VERSION ""

NS_ :

BS_:

BU_: Sensors BPR DIO PDU ELVIS ASSI ECU_LV Dashboard

BO_ 1824 Pushrods_back: 4 Sensors
 SG_ Pushrod_RB : 0|16@1+ (1,0) [0|65535] "" Vector__XXX
 SG_ Pushrod_LB : 16|16@1+ (1,0) [0|65535] "" Vector__XXX

BO_ 1825 Rockers: 4 Sensors
 SG_ Rocker_HAL_R : 16|16@1+ (0.094,-15) [0|360] "deg" Vector__XXX
 SG_ Rocker_HAL_L : 0|16@1+ (0.094,-15) [0|360] "deg" Vector__XXX

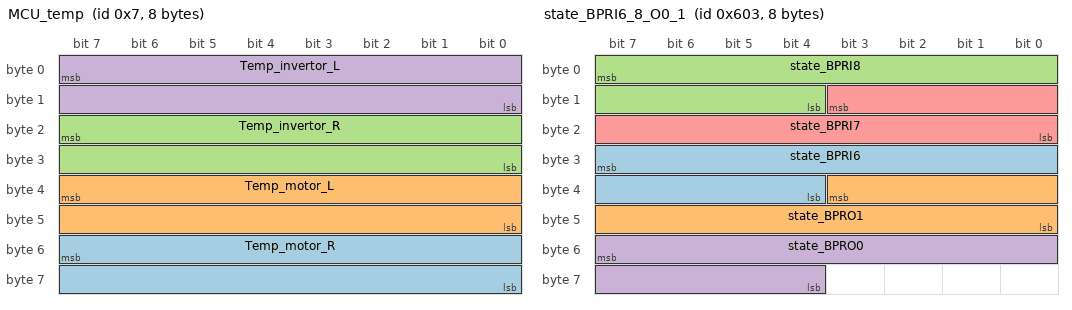
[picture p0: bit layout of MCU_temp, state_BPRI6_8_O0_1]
BO_ 7 MCU_temp: 8 ECU_LV
 SG_ Temp_motor_R : 55|16@0- (0.1,0) [-3276.8|3276.7] "oC" Vector__XXX
 SG_ Temp_motor_L : 39|16@0- (0.1,0) [-3276.8|3276.7] "oC" Vector__XXX
 SG_ Temp_invertor_R : 23|16@0- (0.1,0) [-3276.8|3276.7] "oC" Vector__XXX
 SG_ Temp_invertor_L : 7|16@0- (0.1,0) [-3276.8|3276.7] "oC" Vector__XXX

BO_ 1539 state_BPRI6_8_O0_1: 8 BPR
 SG_ state_BPRI6 : 31|12@0+ (0.008,0) [0|32.76] "mA" Vector__XXX
 SG_ state_BPRO1 : 35|12@0+ (0.008,0) [0|32.76] "mA" Vector__XXX
 SG_ state_BPRI8 : 7|12@0+ (0.008,0) [0|32.76] "mA" Vector__XXX
 SG_ state_BPRO0 : 55|12@0+ (0.008,0) [0|32.76] "mA" Vector__XXX
 SG_ state_BPRI7 : 11|12@0+ (0.008,0) [0|32.76] "mA" Vector__XXX

BO_ 1537 set_BPR: 4 BPR
 SG_ set_BPRO1 : 23|12@0+ (0.008,0) [0|32.76] "mA" Vector__XXX
 SG_ set_BPRO0 : 7|12@0+ (0.008,0) [0|32.76] "mA" Vector__XXX

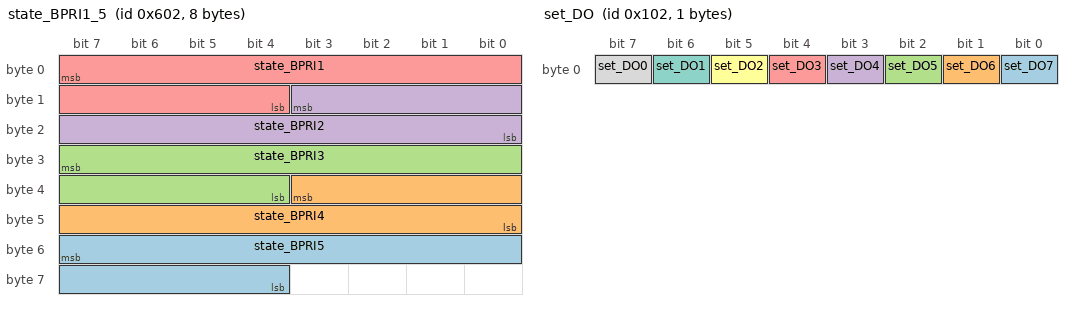
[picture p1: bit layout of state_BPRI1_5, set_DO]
BO_ 1538 state_BPRI1_5: 8 BPR
 SG_ state_BPRI5 : 55|12@0+ (0.008,0) [0|32.76] "mA" Vector__XXX
 SG_ state_BPRI4 : 35|12@0+ (0.008,0) [0|32.76] "mA" Vector__XXX
 SG_ state_BPRI3 : 31|12@0+ (0.008,0) [0|32.76] "mA" Vector__XXX
 SG_ state_BPRI2 : 11|12@0+ (1,0) [0|4095] "V" Vector__XXX
 SG_ state_BPRI1 : 7|12@0+ (1,0) [0|4095] "V" Vector__XXX

BO_ 257 state_DIO: 3 DIO
 SG_ state_DO7 : 22|1@0+ (1,0) [0|1] "" Vector__XXX
 SG_ state_DO6 : 23|1@0+ (1,0) [0|1] "" Vector__XXX
 SG_ state_DO5 : 8|1@0+ (1,0) [0|1] "" Vector__XXX
 SG_ state_DO4 : 9|1@0+ (1,0) [0|1] "" Vector__XXX
 SG_ state_DO3 : 10|1@0+ (1,0) [0|1] "" Vector__XXX
 SG_ state_DO2 : 11|1@0+ (1,0) [0|1] "" Vector__XXX
 SG_ state_DO1 : 12|1@0+ (1,0) [0|1] "" Vector__XXX
 SG_ state_DO0 : 13|1@0+ (1,0) [0|1] "" Vector__XXX
 SG_ state_DI9 : 14|1@0+ (1,0) [0|1] "" Vector__XXX
 SG_ state_DI8 : 15|1@0+ (1,0) [0|1] "" Vector__XXX
 SG_ state_DI7 : 0|1@0+ (1,0) [0|1] "" Vector__XXX
 SG_ state_DI6 : 1|1@0+ (1,0) [0|1] "" Vector__XXX
 SG_ state_DI5 : 2|1@0+ (1,0) [0|1] "" Vector__XXX
 SG_ state_DI4 : 3|1@0+ (1,0) [0|1] "" Vector__XXX
 SG_ state_DI3 : 4|1@0+ (1,0) [0|1] "" Vector__XXX
 SG_ state_DI2 : 5|1@0+ (1,0) [0|1] "" Vector__XXX
 SG_ state_DI1 : 6|1@0+ (1,0) [0|1] "" Vector__XXX
 SG_ state_DI0 : 7|1@0+ (1,0) [0|1] "" Vector__XXX

BO_ 258 set_DO: 1 DIO
 SG_ set_DO7 : 0|1@0+ (1,0) [0|1] "" Vector__XXX
 SG_ set_DO6 : 1|1@0+ (1,0) [0|1] "" Vector__XXX
 SG_ set_DO5 : 2|1@0+ (1,0) [0|1] "" Vector__XXX
 SG_ set_DO4 : 3|1@0+ (1,0) [0|1] "" Vector__XXX
 SG_ set_DO3 : 4|1@0+ (1,0) [0|1] "" Vector__XXX
 SG_ set_DO2 : 5|1@0+ (1,0) [0|1] "" Vector__XXX
 SG_ set_DO1 : 6|1@0+ (1,0) [0|1] "" Vector__XXX
 SG_ set_DO0 : 7|1@0+ (1,0) [0|1] "" Vector__XXX

BO_ 1285 ECU_error: 1 ECU_LV
 SG_ Error_code : 7|8@0+ (1,0) [0|255] "" Vector__XXX

BO_ 1 ECU_State: 1 ECU_LV
 SG_ Orion_state : 3|3@0+ (1,0) [0|6] "" Vector__XXX
 SG_ Heartbeat : 0|1@0+ (1,0) [0|1] "" Vector__XXX

BO_ 277 Brake_pressures: 4 ECU_LV
 SG_ Brake_rear : 23|16@0+ (0.004,0) [0|262.14] "" Vector__XXX
 SG_ Brake_front : 7|16@0+ (0.004,0) [0|262.14] "" Vector__XXX

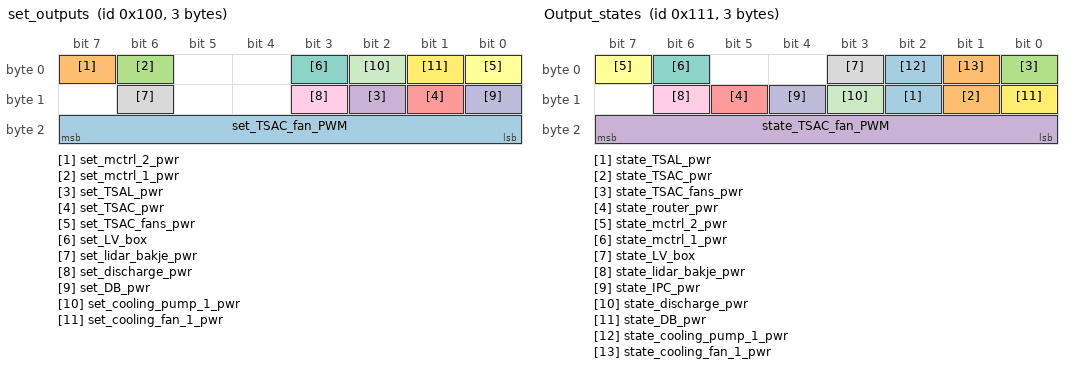
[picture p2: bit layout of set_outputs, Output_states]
BO_ 256 set_outputs: 3 PDU
 SG_ set_TSAC_fan_PWM : 23|8@0+ (1,0) [0|255] "" Vector__XXX
 SG_ set_mctrl_2_pwr : 7|1@0+ (1,0) [0|1] "" Vector__XXX
 SG_ set_mctrl_1_pwr : 6|1@0+ (1,0) [0|1] "" Vector__XXX
 SG_ set_TSAL_pwr : 10|1@0+ (1,0) [0|1] "" Vector__XXX
 SG_ set_TSAC_pwr : 9|1@0+ (1,0) [0|1] "" Vector__XXX
 SG_ set_TSAC_fans_pwr : 0|1@0+ (1,0) [0|1] "" Vector__XXX
 SG_ set_LV_box : 3|1@0+ (1,0) [0|1] "" Vector__XXX
 SG_ set_lidar_bakje_pwr : 14|1@0+ (1,0) [0|1] "" Vector__XXX
 SG_ set_discharge_pwr : 11|1@0+ (1,0) [0|1] "" Vector__XXX
 SG_ set_DB_pwr : 8|1@0+ (1,0) [0|1] "" Vector__XXX
 SG_ set_cooling_pump_1_pwr : 2|1@0+ (1,0) [0|1] "" Vector__XXX
 SG_ set_cooling_fan_1_pwr : 1|1@0+ (1,0) [0|1] "" Vector__XXX

BO_ 273 Output_states: 3 PDU
 SG_ state_TSAL_pwr : 10|1@0+ (1,0) [0|1] "" Vector__XXX
 SG_ state_TSAC_pwr : 9|1@0+ (1,0) [0|1] "" Vector__XXX
 SG_ state_TSAC_fans_pwr : 0|1@0+ (1,0) [0|1] "" Vector__XXX
 SG_ state_TSAC_fan_PWM : 23|8@0+ (1,0) [0|255] "" Vector__XXX
 SG_ state_router_pwr : 13|1@0+ (1,0) [0|1] "" Vector__XXX
 SG_ state_mctrl_2_pwr : 7|1@0+ (1,0) [0|1] "" Vector__XXX
 SG_ state_mctrl_1_pwr : 6|1@0+ (1,0) [0|1] "" Vector__XXX
 SG_ state_LV_box : 3|1@0+ (1,0) [0|1] "" Vector__XXX
 SG_ state_lidar_bakje_pwr : 14|1@0+ (1,0) [0|1] "" Vector__XXX
 SG_ state_IPC_pwr : 12|1@0+ (1,0) [0|1] "" Vector__XXX
 SG_ state_discharge_pwr : 11|1@0+ (1,0) [0|1] "" Vector__XXX
 SG_ state_DB_pwr : 8|1@0+ (1,0) [0|1] "" Vector__XXX
 SG_ state_cooling_pump_1_pwr : 2|1@0+ (1,0) [0|1] "" Vector__XXX
 SG_ state_cooling_fan_1_pwr : 1|1@0+ (1,0) [0|1] "" Vector__XXX

BO_ 272 Inputs: 2 PDU
 SG_ Watercool_temp2 : 15|8@0+ (1,0) [0|255] "" Vector__XXX
 SG_ Watercool_temp1 : 7|8@0+ (1,0) [0|255] "" Vector__XXX

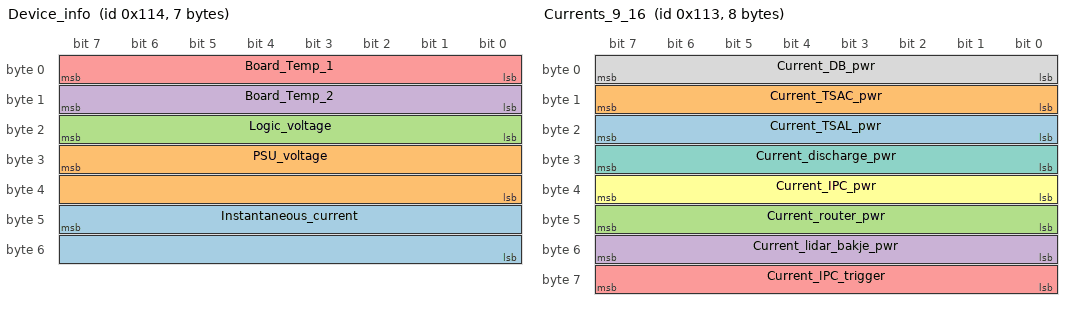
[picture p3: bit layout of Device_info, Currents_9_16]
BO_ 276 Device_info: 7 PDU
 SG_ Instantaneous_current : 47|16@0+ (1,0) [0|65535] "" Vector__XXX
 SG_ PSU_voltage : 31|16@0+ (1,0) [0|65535] "" Vector__XXX
 SG_ Logic_voltage : 23|8@0+ (1,0) [0|255] "" Vector__XXX
 SG_ Board_Temp_2 : 15|8@0+ (1,0) [0|255] "" Vector__XXX
 SG_ Board_Temp_1 : 7|8@0+ (1,0) [0|255] "" Vector__XXX

BO_ 275 Currents_9_16: 8 PDU
 SG_ Current_TSAL_pwr : 23|8@0+ (1,0) [0|255] "" Vector__XXX
 SG_ Current_TSAC_pwr : 15|8@0+ (1,0) [0|255] "" Vector__XXX
 SG_ Current_router_pwr : 47|8@0+ (1,0) [0|255] "" Vector__XXX
 SG_ Current_lidar_bakje_pwr : 55|8@0+ (1,0) [0|255] "" Vector__XXX
 SG_ Current_IPC_trigger : 63|8@0+ (1,0) [0|255] "" Vector__XXX
 SG_ Current_IPC_pwr : 39|8@0+ (1,0) [0|255] "" Vector__XXX
 SG_ Current_discharge_pwr : 31|8@0+ (1,0) [0|255] "" Vector__XXX
 SG_ Current_DB_pwr : 7|8@0+ (1,0) [0|255] "" Vector__XXX

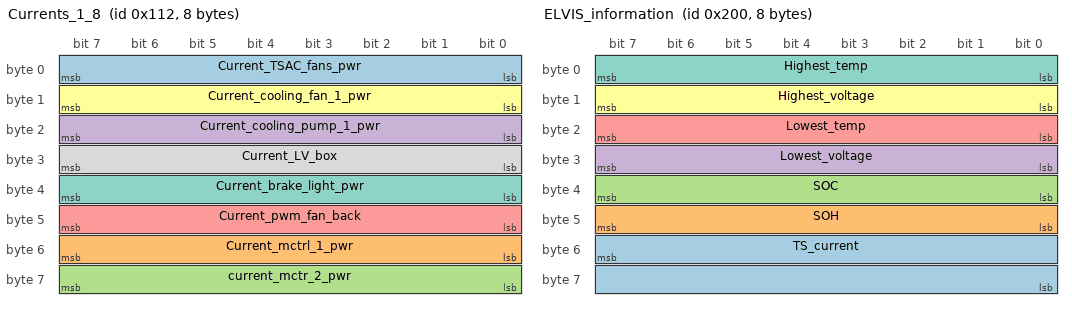
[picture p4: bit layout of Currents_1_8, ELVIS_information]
BO_ 274 Currents_1_8: 8 PDU
 SG_ Current_TSAC_fans_pwr : 7|8@0+ (1,0) [0|255] "" Vector__XXX
 SG_ Current_mctrl_1_pwr : 55|8@0+ (1,0) [0|255] "" Vector__XXX
 SG_ current_mctr_2_pwr : 63|8@0+ (1,0) [0|255] "" Vector__XXX
 SG_ Current_cooling_pump_1_pwr : 23|8@0+ (1,0) [0|255] "" Vector__XXX
 SG_ Current_pwm_fan_back : 47|8@0+ (1,0) [0|255] "" Vector__XXX
 SG_ Current_cooling_fan_1_pwr : 15|8@0+ (1,0) [0|255] "" Vector__XXX
 SG_ Current_brake_light_pwr : 39|8@0+ (1,0) [0|255] "" Vector__XXX
 SG_ Current_LV_box : 31|8@0+ (1,0) [0|255] "" Vector__XXX

BO_ 16 PDU_Heartbeat: 0 PDU

BO_ 768 DB_Commands: 1 Dashboard
 SG_ TS_start : 6|1@0+ (1,0) [0|1] "" Vector__XXX
 SG_ RTD_start : 7|1@0+ (1,0) [0|1] "" Vector__XXX

BO_ 512 ELVIS_information: 8 ELVIS
 SG_ TS_current : 55|16@0+ (1,0) [0|65535] "" Vector__XXX
 SG_ SOH : 47|8@0+ (1,0) [0|255] "" Vector__XXX
 SG_ SOC : 39|8@0+ (1,0) [0|255] "" Vector__XXX
 SG_ Lowest_voltage : 31|8@0+ (1,0) [0|255] "" Vector__XXX
 SG_ Lowest_temp : 23|8@0+ (1,0) [0|255] "" Vector__XXX
 SG_ Highest_voltage : 15|8@0+ (1,0) [0|255] "" Vector__XXX
 SG_ Highest_temp : 7|8@0+ (1,0) [0|255] "" Vector__XXX

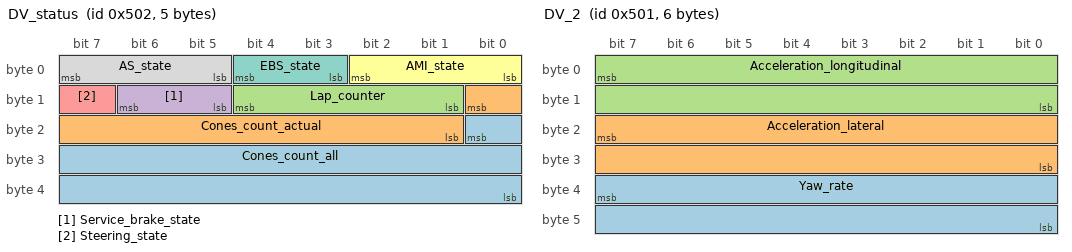
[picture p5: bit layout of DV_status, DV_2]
BO_ 1282 DV_status: 5 ECU_LV
 SG_ Cones_count_all : 16|17@0+ (1,0) [0|131071] "" Vector__XXX
 SG_ Cones_count_actual : 8|8@0+ (1,0) [0|255] "" Vector__XXX
 SG_ Lap_counter : 12|4@0+ (1,0) [0|15] "" Vector__XXX
 SG_ Service_brake_state : 14|2@0+ (1,0) [0|3] "" Vector__XXX
 SG_ Steering_state : 15|1@0+ (1,0) [0|1] "" Vector__XXX
 SG_ AMI_state : 2|3@0+ (1,0) [0|6] "" Vector__XXX
 SG_ EBS_state : 4|2@0+ (1,0) [0|3] "" Vector__XXX
 SG_ AS_state : 7|3@0+ (1,0) [0|5] "" Vector__XXX

BO_ 1281 DV_2: 6 ECU_LV
 SG_ Yaw_rate : 39|16@0- (0.0078125,0) [-256|255.9921875] "deg/s" Vector__XXX
 SG_ Acceleration_lateral : 23|16@0- (0.001953125,0) [-64|63.998046875] "m/s^2" Vector__XXX
 SG_ Acceleration_longitudinal : 7|16@0- (0.001953125,0) [-64|63.998046875] "m/s^2" Vector__XXX

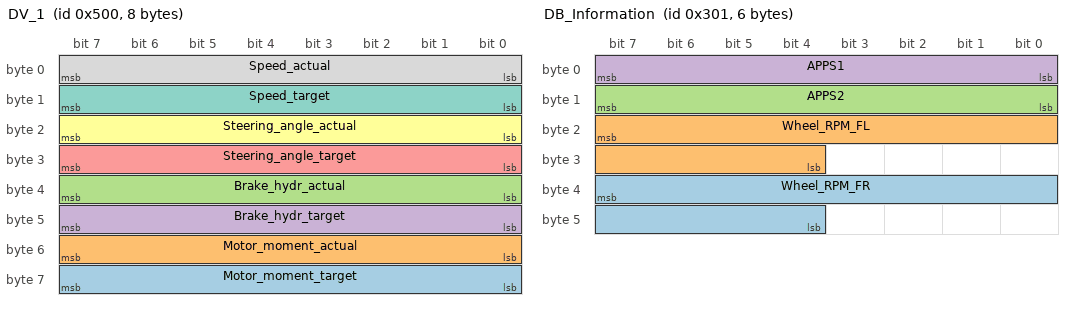
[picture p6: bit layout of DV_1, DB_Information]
BO_ 1280 DV_1: 8 ECU_LV
 SG_ Motor_moment_target : 63|8@0- (1,0) [-100|100] "%" Vector__XXX
 SG_ Motor_moment_actual : 55|8@0- (1,0) [-100|100] "%" Vector__XXX
 SG_ Brake_hydr_actual : 39|8@0+ (1,0) [0|100] "%" Vector__XXX
 SG_ Brake_hydr_target : 47|8@0+ (1,0) [0|100] "%" Vector__XXX
 SG_ Steering_angle_target : 31|8@0- (0.5,0) [-64|63.5] "deg" Vector__XXX
 SG_ Steering_angle_actual : 23|8@0- (0.5,0) [-64|63.5] "deg" Vector__XXX
 SG_ Speed_target : 15|8@0+ (1,0) [0|255] "km/h" Vector__XXX
 SG_ Speed_actual : 7|8@0+ (1,0) [0|255] "km/h" Vector__XXX

BO_ 769 DB_Information: 6 Dashboard
 SG_ Wheel_RPM_FR : 39|12@0+ (1,0) [0|3000] "RPM" Vector__XXX
 SG_ Wheel_RPM_FL : 23|12@0+ (1,0) [0|3000] "RPM" Vector__XXX
 SG_ APPS2 : 15|8@0+ (1,0) [0|100] "%" Vector__XXX
 SG_ APPS1 : 7|8@0+ (1,0) [0|100] "%" Vector__XXX

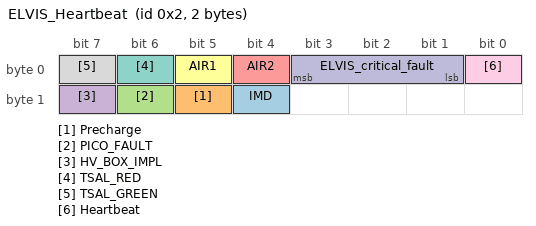
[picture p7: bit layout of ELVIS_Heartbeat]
BO_ 2 ELVIS_Heartbeat: 2 ELVIS
 SG_ IMD : 12|1@0+ (1,0) [0|1] "" Vector__XXX
 SG_ Precharge : 13|1@0+ (1,0) [0|1] "" Vector__XXX
 SG_ PICO_FAULT : 14|1@0+ (1,0) [0|1] "" Vector__XXX
 SG_ HV_BOX_IMPL : 15|1@0+ (1,0) [0|1] "" Vector__XXX
 SG_ AIR2 : 4|1@0+ (1,0) [0|1] "" Vector__XXX
 SG_ AIR1 : 5|1@0+ (1,0) [0|1] "" Vector__XXX
 SG_ TSAL_RED : 6|1@0+ (1,0) [0|1] "" Vector__XXX
 SG_ TSAL_GREEN : 7|1@0+ (1,0) [0|1] "" Vector__XXX
 SG_ Heartbeat : 0|1@0+ (1,0) [0|1] "" Vector__XXX
 SG_ ELVIS_critical_fault : 3|3@0+ (1,0) [0|5] "" Vector__XXX

BO_ 3 DB_Heartbeat: 1 Dashboard
 SG_ Heartbeat : 0|1@0+ (1,0) [0|1] "" Vector__XXX

BO_ 4 ASSI_Heartbeat: 1 ASSI
 SG_ Heartbeat : 0|1@0+ (1,0) [0|1] "" Vector__XXX

CM_ SG_ 256 set_TSAC_fan_PWM "Turn specific output on or off";
CM_ SG_ 256 set_mctrl_2_pwr "Turn specific output on or off";
CM_ SG_ 256 set_mctrl_1_pwr "Turn specific output on or off";
CM_ SG_ 256 set_TSAL_pwr "Turn specific output on or off";
CM_ SG_ 256 set_TSAC_pwr "Turn specific output on or off";
CM_ SG_ 256 set_TSAC_fans_pwr "Turn specific output on or off";
CM_ SG_ 256 set_LV_box "Turn specific output on or off";
CM_ SG_ 256 set_lidar_bakje_pwr "Turn specific output on or off";
CM_ SG_ 256 set_discharge_pwr "Turn specific output on or off";
CM_ SG_ 256 set_DB_pwr "Turn specific output on or off";
CM_ SG_ 256 set_cooling_pump_1_pwr "Turn specific output on or off";
CM_ SG_ 256 set_cooling_fan_1_pwr "Turn specific output on or off";
CM_ SG_ 273 state_TSAL_pwr "Turn specific output on or off";
CM_ SG_ 273 state_TSAC_pwr "Turn specific output on or off";
CM_ SG_ 273 state_TSAC_fans_pwr "Turn specific output on or off";
CM_ SG_ 273 state_TSAC_fan_PWM "Turn specific output on or off";
CM_ SG_ 273 state_router_pwr "Turn specific output on or off";
CM_ SG_ 273 state_mctrl_2_pwr "Turn specific output on or off";
CM_ SG_ 273 state_mctrl_1_pwr "Turn specific output on or off";
CM_ SG_ 273 state_LV_box "Turn specific output on or off";
CM_ SG_ 273 state_lidar_bakje_pwr "Turn specific output on or off";
CM_ SG_ 273 state_IPC_pwr "Turn specific output on or off";
CM_ SG_ 273 state_discharge_pwr "Turn specific output on or off";
CM_ SG_ 273 state_DB_pwr "Turn specific output on or off";
CM_ SG_ 273 state_cooling_pump_1_pwr "Turn specific output on or off";
CM_ SG_ 273 state_cooling_fan_1_pwr "Turn specific output on or off";
VAL_ 1 Orion_state 7 "ERROR_EXT" 6 "ERROR_INT" 5 "R2D" 4 "R2D_READY" 3 "TS_ACTIVE" 2 "TS_ACTIVATING" 1 "TS_READY" 0 "INIT" ;
VAL_ 1282 Service_brake_state 3 "available" 2 "engaged" 1 "disengaged" 0 "UNKNOWN" ;
VAL_ 1282 AMI_state 5 "inspection" 6 "autocross" 4 "braketest" 3 "trackdrive" 2 "skidpad" 1 "acceleration" 0 "UNKNOWN" ;
VAL_ 1282 EBS_state 2 "armed" 3 "activated" 1 "unavailable" 0 "UNKNOWN" ;
VAL_ 1282 AS_state 5 "finish" 4 "emergency_brake" 3 "driving" 2 "ready" 1 "off" 0 "unknown" ;
VAL_ 2 ELVIS_critical_fault 5 "OVERTEMPERATURE" 4 "UNDERTEMPERATURE" 3 "OVERVOLTAGE" 2 "UNDERVOLTAGE" 1 "OKAY" 0 "UNKNOWN_FAULT" ;
